# ATSAM4CMS32C_1 device description
Architecture: CORTEX-M4; Family: SAM4; Series: SAM4CM
Registers are 32-bit, read-write, no defined reset value unless marked. A register's access mark holds for its fields unless they carry their own. Offsets are from the block's base; [hi:lo] are bit positions; {n}, {i} and the like mark numbered series.

## RSTC — Reset Controller
Instances: RSTC 0x400E1400
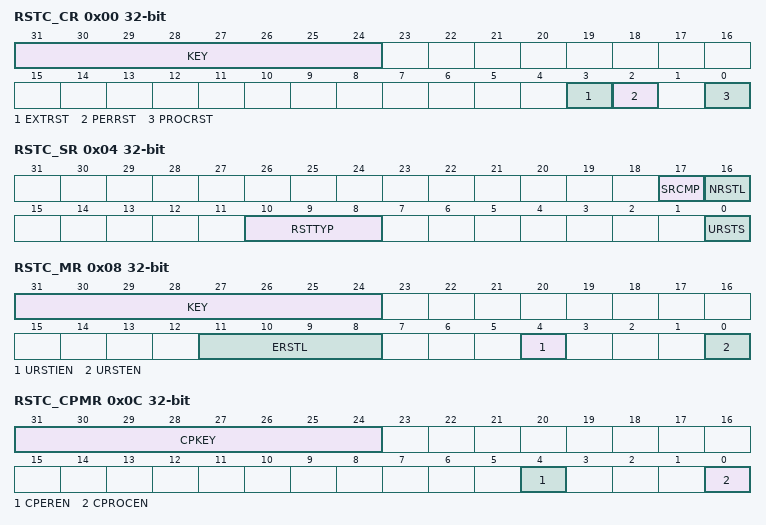
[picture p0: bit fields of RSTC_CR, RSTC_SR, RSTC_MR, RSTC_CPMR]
0x00 RSTC_CR wo — Control Register
  [31:24] KEY — System Reset Key
    165=PASSWD (Writing any other value in this field aborts the write operation.)
  [3] EXTRST — External Reset
  [2] PERRST — Peripheral Reset
  [0] PROCRST — Processor Reset
0x04 RSTC_SR ro — Status Register
  [17] SRCMP — Software Reset Command in Progress
  [16] NRSTL — NRST Pin Level
  [10:8] RSTTYP — Reset Type
    0=GENERAL_RST (First power-up reset); 1=BACKUP_RST (Return from Backup Mode); 2=WDT_RST (Watchdog fault occurred); 3=SOFT_RST (Processor reset required by the software); 4=USER_RST (NRST pin detected low)
  [0] URSTS — User Reset Status
0x08 RSTC_MR — Mode Register
  [31:24] KEY — Write Access Password
    165=PASSWD (Writing any other value in this field aborts the write operation.Always reads as 0.)
  [11:8] ERSTL — External Reset Length
  [4] URSTIEN — User Reset Interrupt Enable
  [0] URSTEN — User Reset Enable
0x0C RSTC_CPMR — Coprocessor Mode Register
  [31:24] CPKEY — Coprocessor System Enable Key
    90=PASSWD (Writing any other value in this field aborts the write operation.)
  [4] CPEREN — Coprocessor Peripheral Enable
  [0] CPROCEN — Coprocessor (Second Processor) Enable

## RSWDT — Reinforced Safety Watchdog Timer
Instances: RSWDT 0x400E1500
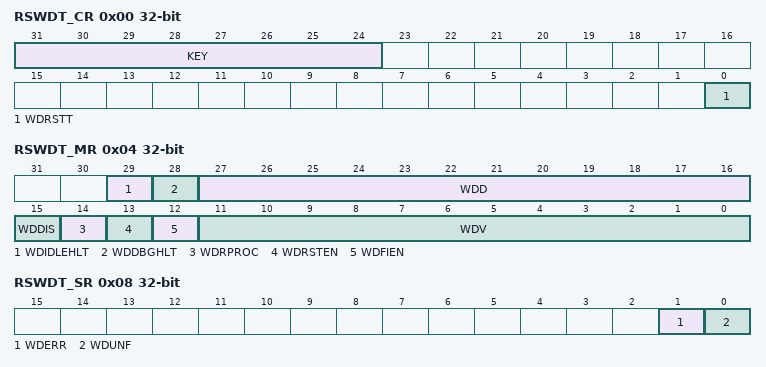
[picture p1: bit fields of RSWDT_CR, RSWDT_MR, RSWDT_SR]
0x00 RSWDT_CR wo — Control Register
  [31:24] KEY — Password
    196=PASSWD (Writing any other value in this field aborts the write operation.)
  [0] WDRSTT — Watchdog Restart
0x04 RSWDT_MR — Mode Register
  [29] WDIDLEHLT — Watchdog Idle Halt
  [28] WDDBGHLT — Watchdog Debug Halt
  [27:16] WDD — Watchdog Delta Value
  [15] WDDIS — Watchdog Disable
  [14] WDRPROC — Watchdog Reset Processor
  [13] WDRSTEN — Watchdog Reset Enable
  [12] WDFIEN — Watchdog Fault Interrupt Enable
  [11:0] WDV — Watchdog Counter Value
0x08 RSWDT_SR ro — Status Register
  [1] WDERR — Watchdog Error
  [0] WDUNF — Watchdog Underflow

## WDT — Watchdog Timer
Instances: WDT 0x400E1450
Registers as RSWDT (with RSWDT read as WDT); these are added or differ:
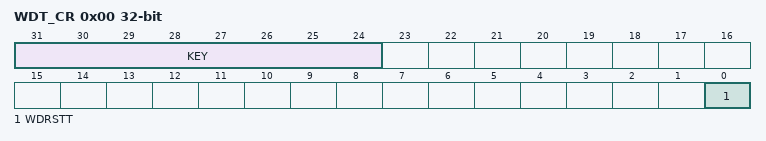
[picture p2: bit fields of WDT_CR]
0x00 WDT_CR wo — Control Register
  [31:24] KEY — Password.
    165=PASSWD (Writing any other value in this field aborts the write operation.)
  [0] WDRSTT — Watchdog Restart

## RTT — Real-time Timer
Instances: RTT 0x400E1430
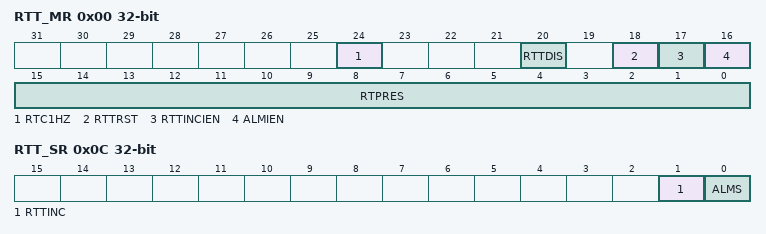
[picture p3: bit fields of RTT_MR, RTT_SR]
0x00 RTT_MR — Mode Register
  [24] RTC1HZ — Real-Time Clock 1Hz Clock Selection
  [20] RTTDIS — Real-time Timer Disable
  [18] RTTRST — Real-time Timer Restart
  [17] RTTINCIEN — Real-time Timer Increment Interrupt Enable
  [16] ALMIEN — Alarm Interrupt Enable
  [15:0] RTPRES — Real-time Timer Prescaler Value
0x04 RTT_AR — Alarm Register
  [31:0] ALMV — Alarm Value
0x08 RTT_VR ro — Value Register
  [31:0] CRTV — Current Real-time Value
0x0C RTT_SR ro — Status Register
  [1] RTTINC — Prescaler Roll-over Status
  [0] ALMS — Real-time Alarm Status

## SMC — Static Memory Controller
Instances: SMC0 0x400E0000, SMC1 0x4801C000
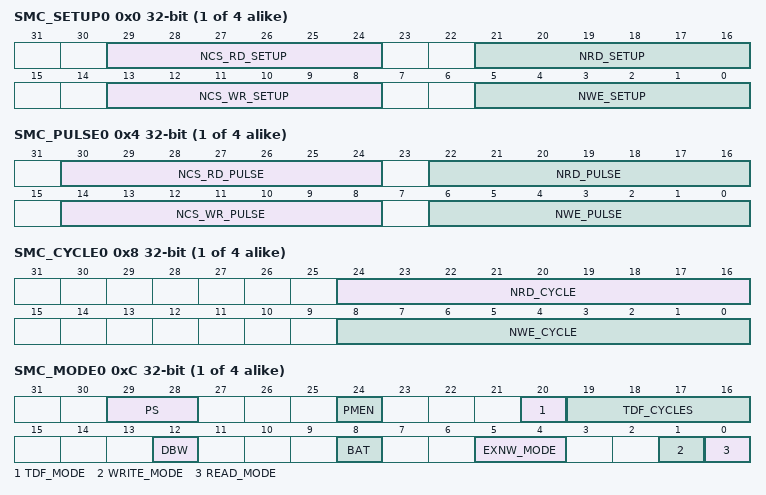
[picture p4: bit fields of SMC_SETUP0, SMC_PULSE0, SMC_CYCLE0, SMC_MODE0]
{0x0+0x10*i} SMC_SETUP{i} (i=0..3) — SMC Setup Register (CS_number = {i})
  [29:24] NCS_RD_SETUP — NCS Setup Length in READ Access
  [21:16] NRD_SETUP — NRD Setup Length
  [13:8] NCS_WR_SETUP — NCS Setup Length in WRITE Access
  [5:0] NWE_SETUP — NWE Setup Length
{0x4+0x10*i} SMC_PULSE{i} (i=0..3) — SMC Pulse Register (CS_number = {i})
  [30:24] NCS_RD_PULSE — NCS Pulse Length in READ Access
  [22:16] NRD_PULSE — NRD Pulse Length
  [14:8] NCS_WR_PULSE — NCS Pulse Length in WRITE Access
  [6:0] NWE_PULSE — NWE Pulse Length
{0x8+0x10*i} SMC_CYCLE{i} (i=0..3) — SMC Cycle Register (CS_number = {i})
  [24:16] NRD_CYCLE — Total Read Cycle Length
  [8:0] NWE_CYCLE — Total Write Cycle Length
{0xC+0x10*i} SMC_MODE{i} (i=0..3) — SMC Mode Register (CS_number = {i})
  [29:28] PS — Page Size
    0=_4_BYTE (4-byte page); 1=_8_BYTE (8-byte page); 2=_16_BYTE (16-byte page); 3=_32_BYTE (32-byte page)
  [24] PMEN — Page Mode Enabled
  [20] TDF_MODE — TDF Optimization
  [19:16] TDF_CYCLES — Data Float Time
  [12] DBW — Data Bus Width
    0=_8_BIT (8-bit Data Bus); 1=_16_BIT (16-bit Data Bus)
  [8] BAT — Byte Access Type
    0=BYTE_SELECT (Byte select access type:- Write operation is controlled using NCS, NWE, NBS0, NBS1.- Read operation is controlled using NCS, NRD, NBS0, NBS1.); 1=BYTE_WRITE (Byte write access type:- Write operation is controlled using NCS, NWR0, NWR1.- Read operation is controlled using NCS and NRD.)
  [5:4] EXNW_MODE — NWAIT Mode
    0=DISABLED; 2=FROZEN (Frozen Mode); 3=READY (Ready Mode)
  [1] WRITE_MODE
  [0] READ_MODE
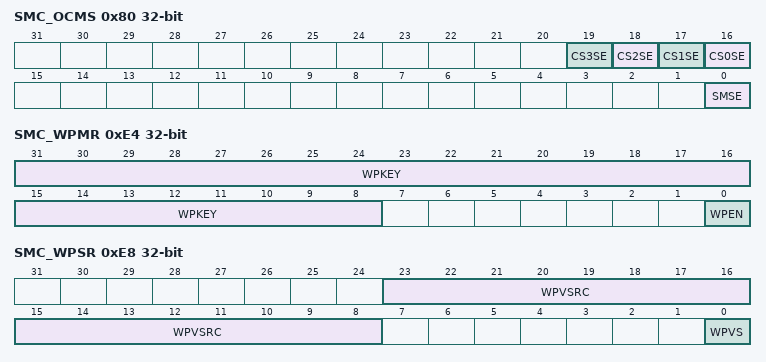
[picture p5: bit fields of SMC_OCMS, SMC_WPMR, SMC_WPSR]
0x80 SMC_OCMS — SMC OCMS MODE Register
  [n+16] CS{n}SE (n=0..3) — Chip Select (x = 0 to 3) Scrambling Enable
  [0] SMSE — Static Memory Controller Scrambling EnableSAM4C0x00030003CS0SECS1SECS1SECS2SECS3SE
0x84 SMC_KEY1 wo — SMC OCMS KEY1 Register
  [31:0] KEY1 — Off Chip Memory Scrambling (OCMS) Key Part 1
0x88 SMC_KEY2 wo — SMC OCMS KEY2 Register
  [31:0] KEY2 — Off Chip Memory Scrambling (OCMS) Key Part 2
0xE4 SMC_WPMR — SMC Write Protect Mode Register
  [31:8] WPKEY — Write Protect KEY
  [0] WPEN — Write Protect Enable
0xE8 SMC_WPSR ro — SMC Write Protect Status Register
  [23:8] WPVSRC — Write Protect Violation Source
  [0] WPVS — Write Protect Enable
